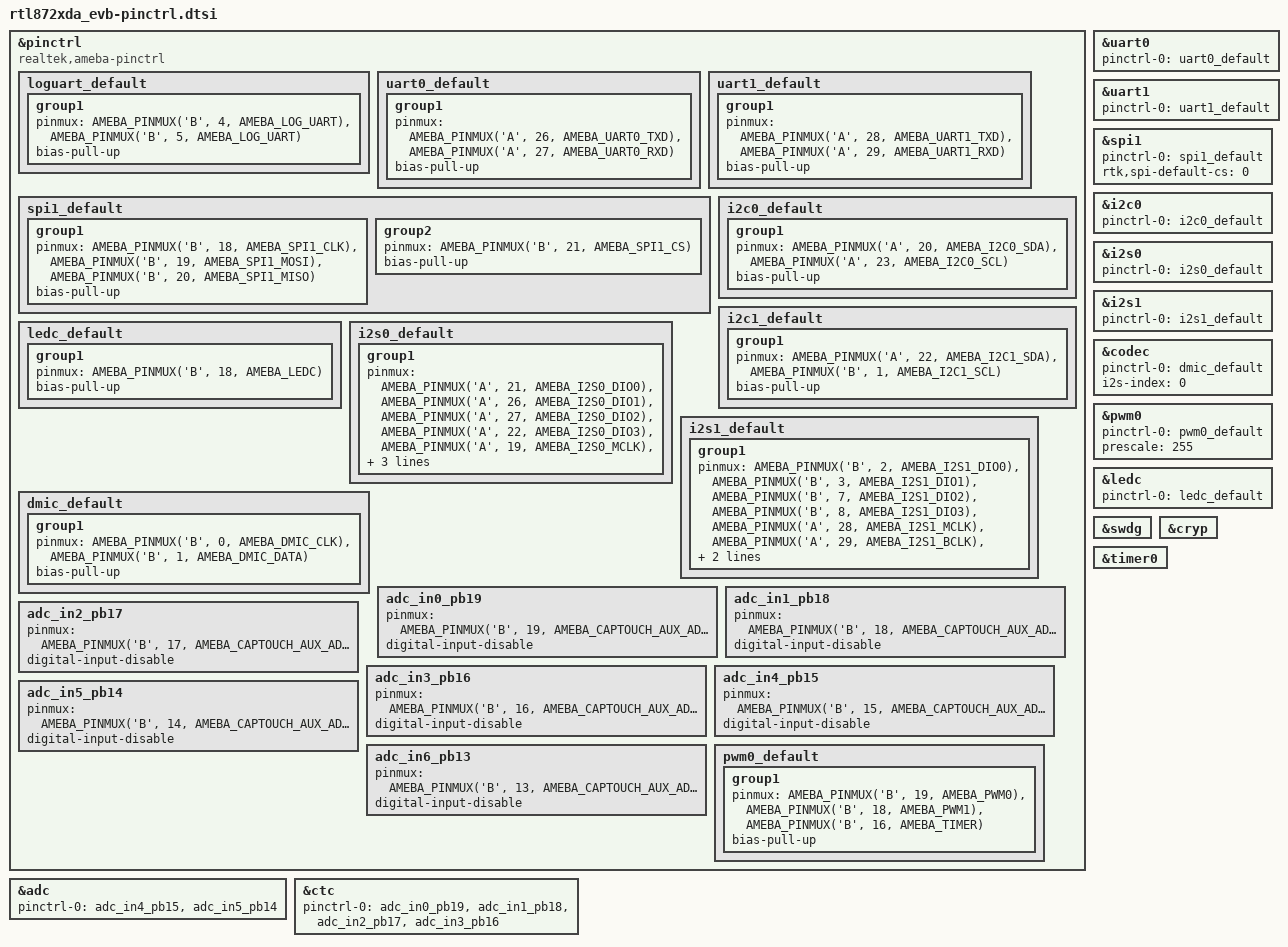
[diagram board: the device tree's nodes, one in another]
/*
 * Copyright (c) 2024 Realtek Semiconductor Corp.
 *
 * SPDX-License-Identifier: Apache-2.0
 */

#include <zephyr/dt-bindings/pinctrl/amebadplus-pinctrl.h>

&pinctrl {
	compatible = "realtek,ameba-pinctrl";

	/*PA30 is SWD_CLK, PA31 is SWD_DAT(both pull-up internally)*/
	loguart_default: loguart_default {
		group1 {
			pinmux = <AMEBA_PINMUX('B', 4, AMEBA_LOG_UART)>,        /* RXD */
					 <AMEBA_PINMUX('B', 5, AMEBA_LOG_UART)>;        /* TXD */
			bias-pull-up;
		};
	};

	uart0_default: uart0_default {
		group1 {
			pinmux = <AMEBA_PINMUX('A', 26, AMEBA_UART0_TXD)>,
					 <AMEBA_PINMUX('A', 27, AMEBA_UART0_RXD)>;
			bias-pull-up;
		};
	};

	uart1_default: uart1_default {
		group1 {
			pinmux = <AMEBA_PINMUX('A', 28, AMEBA_UART1_TXD)>,
					 <AMEBA_PINMUX('A', 29, AMEBA_UART1_RXD)>;
			bias-pull-up;
		};
	};

	spi1_default: spi1_default {
		group1 {
			pinmux = <AMEBA_PINMUX('B', 18, AMEBA_SPI1_CLK)>,
					 <AMEBA_PINMUX('B', 19, AMEBA_SPI1_MOSI)>,
					 <AMEBA_PINMUX('B', 20, AMEBA_SPI1_MISO)>;
			bias-pull-up;
		};
		group2 {
			pinmux = <AMEBA_PINMUX('B', 21, AMEBA_SPI1_CS)>;
			bias-pull-up;
		};
	};

	i2c0_default: i2c0_default {
		group1 {
			pinmux = <AMEBA_PINMUX('A', 20, AMEBA_I2C0_SDA)>,
					 <AMEBA_PINMUX('A', 23, AMEBA_I2C0_SCL)>;
			bias-pull-up;
		};
	};

	i2c1_default: i2c1_default {
		group1 {
			pinmux = <AMEBA_PINMUX('A', 22, AMEBA_I2C1_SDA)>,
					 <AMEBA_PINMUX('B',  1, AMEBA_I2C1_SCL)>;
			bias-pull-up;
		};
	};

	ledc_default: ledc_default {
		group1 {
			pinmux = <AMEBA_PINMUX('B', 18, AMEBA_LEDC)>;
			bias-pull-up;
		};
	};

	i2s0_default: i2s0_default {
		group1 {
			pinmux = <AMEBA_PINMUX('A', 21, AMEBA_I2S0_DIO0)>,
					 <AMEBA_PINMUX('A', 26, AMEBA_I2S0_DIO1)>,
					 <AMEBA_PINMUX('A', 27, AMEBA_I2S0_DIO2)>,
					 <AMEBA_PINMUX('A', 22, AMEBA_I2S0_DIO3)>,
					 <AMEBA_PINMUX('A', 19, AMEBA_I2S0_MCLK)>,
					 <AMEBA_PINMUX('A', 23, AMEBA_I2S0_BCLK)>,
					 <AMEBA_PINMUX('A', 20, AMEBA_I2S0_WS)>;
			bias-pull-up;
		};
	};

	i2s1_default: i2s1_default {
		group1 {
			pinmux = <AMEBA_PINMUX('B',  2, AMEBA_I2S1_DIO0)>,
					 <AMEBA_PINMUX('B',  3, AMEBA_I2S1_DIO1)>,
					 <AMEBA_PINMUX('B',  7, AMEBA_I2S1_DIO2)>,
					 <AMEBA_PINMUX('B',  8, AMEBA_I2S1_DIO3)>,
					 <AMEBA_PINMUX('A', 28, AMEBA_I2S1_MCLK)>,
					 <AMEBA_PINMUX('A', 29, AMEBA_I2S1_BCLK)>,
					 <AMEBA_PINMUX('B',  1, AMEBA_I2S1_WS)>;
			bias-pull-up;
		};
	};

	dmic_default: dmic_default {
		group1 {
			pinmux = <AMEBA_PINMUX('B', 0, AMEBA_DMIC_CLK)>,
					 <AMEBA_PINMUX('B', 1, AMEBA_DMIC_DATA)>;
			bias-pull-up;
		};
	};

	/* NOTE: PB16~PB19 CANNOT be selected by ADC and CTC simultaneously!!! */
	/omit-if-no-ref/ adc_in0_pb19: adc_in0_pb19 {
		pinmux = <AMEBA_PINMUX('B', 19, AMEBA_CAPTOUCH_AUX_ADC)>;
		digital-input-disable;
	};

	/omit-if-no-ref/ adc_in1_pb18: adc_in1_pb18 {
		pinmux = <AMEBA_PINMUX('B', 18, AMEBA_CAPTOUCH_AUX_ADC)>;
		digital-input-disable;
	};

	/omit-if-no-ref/ adc_in2_pb17: adc_in2_pb17 {
		pinmux = <AMEBA_PINMUX('B', 17, AMEBA_CAPTOUCH_AUX_ADC)>;
		digital-input-disable;
	};

	/omit-if-no-ref/ adc_in3_pb16: adc_in3_pb16 {
		pinmux = <AMEBA_PINMUX('B', 16, AMEBA_CAPTOUCH_AUX_ADC)>;
		digital-input-disable;
	};

	/omit-if-no-ref/ adc_in4_pb15: adc_in4_pb15 {
		pinmux = <AMEBA_PINMUX('B', 15, AMEBA_CAPTOUCH_AUX_ADC)>;
		digital-input-disable;
	};

	/omit-if-no-ref/ adc_in5_pb14: adc_in5_pb14 {
		pinmux = <AMEBA_PINMUX('B', 14, AMEBA_CAPTOUCH_AUX_ADC)>;
		digital-input-disable;
	};

	/omit-if-no-ref/ adc_in6_pb13: adc_in6_pb13 {
		pinmux = <AMEBA_PINMUX('B', 13, AMEBA_CAPTOUCH_AUX_ADC)>;
		digital-input-disable;
	};

	pwm0_default: pwm0_default {
		group1 {
			pinmux = <AMEBA_PINMUX('B', 19, AMEBA_PWM0)>, /* Channel 0 Output Pin */
					 <AMEBA_PINMUX('B', 18, AMEBA_PWM1)>,
					 <AMEBA_PINMUX('B', 16, AMEBA_TIMER)>; /* TRGI */
			bias-pull-up;
		};
	};
};

&uart0 {
	pinctrl-0 = <&uart0_default>;
	pinctrl-names = "default";
	status = "okay";
};

&uart1 {
	pinctrl-0 = <&uart1_default>;
	pinctrl-names = "default";
};

&spi1 {
	pinctrl-0 = <&spi1_default>;
	pinctrl-names = "default";
	rtk,spi-default-cs = <0>;
	status = "okay";
};

&i2c0 {
	pinctrl-0 = <&i2c0_default>;
	pinctrl-names = "default";
	status = "okay";
};

&i2s0 {
	pinctrl-0 = <&i2s0_default>;
	pinctrl-names = "default";
	status = "okay";
};

&i2s1 {
	pinctrl-0 = <&i2s1_default>;
	pinctrl-names = "default";
};

&codec {
	pinctrl-0 = <&dmic_default>;
	pinctrl-names = "default";
	i2s-index = <0>;
	status = "okay";
};

&adc {
	pinctrl-0 = <&adc_in4_pb15 &adc_in5_pb14>;
	pinctrl-names = "default";
	status = "okay";
};

&ctc {
	pinctrl-0 = <&adc_in0_pb19 &adc_in1_pb18 &adc_in2_pb17 &adc_in3_pb16>;
	pinctrl-names = "default";
	status = "okay";
};

&pwm0 {
	pinctrl-0 = <&pwm0_default>;
	pinctrl-names = "default";
	prescale = <255>;
	status = "okay";
};

&ledc {
	pinctrl-names = "default";
	pinctrl-0 = <&ledc_default>;
	status = "okay";
};

&swdg {
	status = "okay";
};

&cryp {
	status = "okay";
};

&timer0 {
	status = "okay";
};
